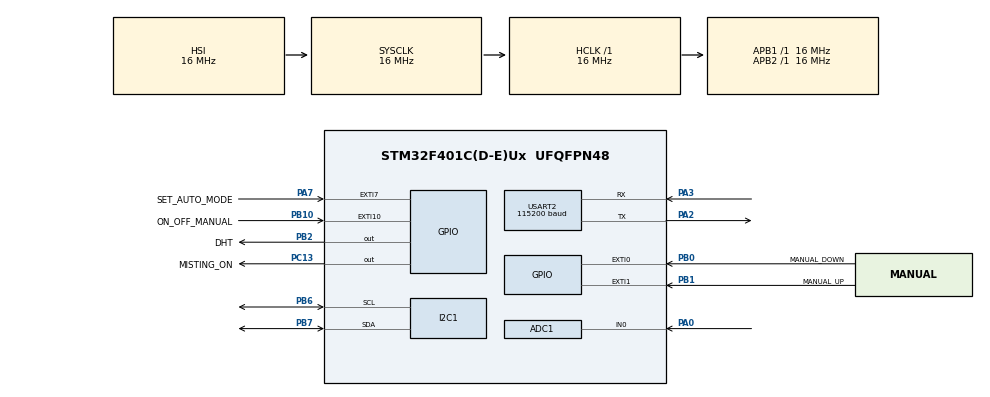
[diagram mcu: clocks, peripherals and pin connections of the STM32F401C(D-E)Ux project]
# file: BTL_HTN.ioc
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ADC1.Channel-0\#ChannelRegularConversion=ADC_CHANNEL_0
ADC1.NbrOfConversionFlag=1
ADC1.Rank-0\#ChannelRegularConversion=1
ADC1.SamplingTime-0\#ChannelRegularConversion=ADC_SAMPLETIME_3CYCLES
ADC1.master=1
Mcu.Family=STM32F4
Mcu.Name=STM32F401C(D-E)Ux
Mcu.Package=UFQFPN48
NVIC.EXTI0_IRQn=true\:4\:0\:true\:false\:true\:true\:true\:true
NVIC.EXTI15_10_IRQn=true\:4\:0\:true\:false\:true\:true\:true\:true
NVIC.EXTI1_IRQn=true\:4\:0\:true\:false\:true\:true\:true\:true
NVIC.EXTI9_5_IRQn=true\:4\:0\:true\:false\:true\:true\:true\:true
NVIC.PriorityGroup=NVIC_PRIORITYGROUP_4
NVIC.TIM3_IRQn=true\:4\:0\:true\:false\:true\:true\:true\:true
NVIC.TIM4_IRQn=true\:4\:0\:true\:false\:true\:true\:true\:true
NVIC.TIM5_IRQn=true\:5\:0\:true\:false\:true\:true\:true\:true
NVIC.USART2_IRQn=true\:3\:0\:true\:false\:true\:true\:true\:true
PA0-WKUP.Signal=ADCx_IN0
PA13.Mode=Serial_Wire
PA13.Signal=SYS_JTMS-SWDIO
PA14.Mode=Serial_Wire
PA14.Signal=SYS_JTCK-SWCLK
PA2.Mode=Asynchronous
PA2.Signal=USART2_TX
PA3.Mode=Asynchronous
PA3.Signal=USART2_RX
PA7.GPIO_Label=SET_AUTO_MODE
PA7.GPIO_ModeDefaultEXTI=GPIO_MODE_IT_FALLING
PA7.GPIO_PuPd=GPIO_PULLDOWN
PA7.Signal=GPXTI7
PB0.GPIO_Label=MANUAL_DOWN
PB0.GPIO_ModeDefaultEXTI=GPIO_MODE_IT_FALLING
PB0.GPIO_PuPd=GPIO_PULLDOWN
PB0.Signal=GPXTI0
PB1.GPIO_Label=MANUAL_UP
PB1.GPIO_ModeDefaultEXTI=GPIO_MODE_IT_FALLING
PB1.GPIO_PuPd=GPIO_PULLDOWN
PB1.Signal=GPXTI1
PB10.GPIO_Label=ON_OFF_MANUAL
PB10.GPIO_ModeDefaultEXTI=GPIO_MODE_IT_FALLING
PB10.GPIO_PuPd=GPIO_PULLDOWN
PB10.Signal=GPXTI10
PB2.GPIO_Label=DHT
PB2.Signal=GPIO_Output
PB6.Mode=I2C
PB6.Signal=I2C1_SCL
PB7.Mode=I2C
PB7.Signal=I2C1_SDA
PC13-ANTI_TAMP.GPIO_Label=MISTING_ON
PC13-ANTI_TAMP.Signal=GPIO_Output
ProjectManager.HeapSize=0x200
ProjectManager.StackSize=0x400
ProjectManager.TargetToolchain=STM32CubeIDE
RCC.AHBFreq_Value=16000000
RCC.APB1Freq_Value=16000000
RCC.APB2Freq_Value=16000000
RCC.CortexFreq_Value=16000000
RCC.HSE_VALUE=25000000
RCC.HSI_VALUE=16000000
RCC.LSE_VALUE=32768
RCC.SYSCLKFreq_VALUE=16000000
RCC.VCOOutputFreq_Value=192000000
SH.ADCx_IN0.0=ADC1_IN0,IN0
TIM2.Prescaler=15
TIM3.Period=399
TIM3.Prescaler=799
TIM4.Period=4999
TIM4.Prescaler=15999
TIM5.Period=49999
TIM5.Prescaler=159
USART2.BaudRate=115200
USART2.VirtualMode=VM_ASYNC
VP_TIM2_VS_ClockSourceINT.Mode=Internal
VP_TIM3_VS_ClockSourceINT.Mode=Internal
VP_TIM4_VS_ClockSourceINT.Mode=Internal
VP_TIM5_VS_ClockSourceINT.Mode=Internal
board=custom

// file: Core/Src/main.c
/* USER CODE BEGIN Header */
/**
  ******************************************************************************
  * @file           : main.c
  * @brief          : Main program body
  ******************************************************************************
  * @attention
  *
  * Copyright (c) 2025 STMicroelectronics.
  * All rights reserved.
  *
  * This software is licensed under terms that can be found in the LICENSE file
  * in the root directory of this software component.
  * If no LICENSE file comes with this software, it is provided AS-IS.
  *
  ******************************************************************************
  */
/* USER CODE END Header */
#include "main.h"

/* USER CODE BEGIN Includes */
#include "app.h"

/* USER CODE END Includes */

ADC_HandleTypeDef hadc1;

I2C_HandleTypeDef hi2c1;

TIM_HandleTypeDef htim2;
TIM_HandleTypeDef htim3;
TIM_HandleTypeDef htim4;
TIM_HandleTypeDef htim5;

UART_HandleTypeDef huart2;

void SystemClock_Config(void);
static void MX_GPIO_Init(void);
static void MX_ADC1_Init(void);
static void MX_TIM3_Init(void);
static void MX_TIM2_Init(void);
static void MX_I2C1_Init(void);
static void MX_USART2_UART_Init(void);
static void MX_TIM4_Init(void);
static void MX_TIM5_Init(void);

int main(void)
{

  /* MCU Configuration--------------------------------------------------------*/

  /* Reset of all peripherals, Initializes the Flash interface and the Systick. */
  HAL_Init();

  /* Configure the system clock */
  SystemClock_Config();

  /* Initialize all configured peripherals */
  MX_GPIO_Init();
  MX_ADC1_Init();
  MX_TIM3_Init();
  MX_TIM2_Init();
  MX_I2C1_Init();
  MX_USART2_UART_Init();
  MX_TIM4_Init();
  MX_TIM5_Init();
  /* USER CODE BEGIN 2 */

	Air_Monitor_Main();
  /* USER CODE END 2 */

  /* Infinite loop */
  while (1)
  {

  }
}

void SystemClock_Config(void)
{
  RCC_OscInitTypeDef RCC_OscInitStruct = {0};
  RCC_ClkInitTypeDef RCC_ClkInitStruct = {0};

  /** Configure the main internal regulator output voltage
  */
  __HAL_RCC_PWR_CLK_ENABLE();
  __HAL_PWR_VOLTAGESCALING_CONFIG(PWR_REGULATOR_VOLTAGE_SCALE2);

  /** Initializes the RCC Oscillators according to the specified parameters
  * in the RCC_OscInitTypeDef structure.
  */
  RCC_OscInitStruct.OscillatorType = RCC_OSCILLATORTYPE_HSI;
  RCC_OscInitStruct.HSIState = RCC_HSI_ON;
  RCC_OscInitStruct.HSICalibrationValue = RCC_HSICALIBRATION_DEFAULT;
  RCC_OscInitStruct.PLL.PLLState = RCC_PLL_NONE;
  if (HAL_RCC_OscConfig(&RCC_OscInitStruct) != HAL_OK)
  {
    Error_Handler();
  }

  /** Initializes the CPU, AHB and APB buses clocks
  */
  RCC_ClkInitStruct.ClockType = RCC_CLOCKTYPE_HCLK|RCC_CLOCKTYPE_SYSCLK
                              |RCC_CLOCKTYPE_PCLK1|RCC_CLOCKTYPE_PCLK2;
  RCC_ClkInitStruct.SYSCLKSource = RCC_SYSCLKSOURCE_HSI;
  RCC_ClkInitStruct.AHBCLKDivider = RCC_SYSCLK_DIV1;
  RCC_ClkInitStruct.APB1CLKDivider = RCC_HCLK_DIV1;
  RCC_ClkInitStruct.APB2CLKDivider = RCC_HCLK_DIV1;

  if (HAL_RCC_ClockConfig(&RCC_ClkInitStruct, FLASH_LATENCY_0) != HAL_OK)
  {
    Error_Handler();
  }
}

static void MX_ADC1_Init(void)
{

  ADC_ChannelConfTypeDef sConfig = {0};

  /** Configure the global features of the ADC (Clock, Resolution, Data Alignment and number of conversion)
  */
  hadc1.Instance = ADC1;
  hadc1.Init.ClockPrescaler = ADC_CLOCK_SYNC_PCLK_DIV2;
  hadc1.Init.Resolution = ADC_RESOLUTION_12B;
  hadc1.Init.ScanConvMode = DISABLE;
  hadc1.Init.ContinuousConvMode = DISABLE;
  hadc1.Init.DiscontinuousConvMode = DISABLE;
  hadc1.Init.ExternalTrigConvEdge = ADC_EXTERNALTRIGCONVEDGE_NONE;
  hadc1.Init.ExternalTrigConv = ADC_SOFTWARE_START;
  hadc1.Init.DataAlign = ADC_DATAALIGN_RIGHT;
  hadc1.Init.NbrOfConversion = 1;
  hadc1.Init.DMAContinuousRequests = DISABLE;
  hadc1.Init.EOCSelection = ADC_EOC_SINGLE_CONV;
  if (HAL_ADC_Init(&hadc1) != HAL_OK)
  {
    Error_Handler();
  }

  /** Configure for the selected ADC regular channel its corresponding rank in the sequencer and its sample time.
  */
  sConfig.Channel = ADC_CHANNEL_0;
  sConfig.Rank = 1;
  sConfig.SamplingTime = ADC_SAMPLETIME_3CYCLES;
  if (HAL_ADC_ConfigChannel(&hadc1, &sConfig) != HAL_OK)
  {
    Error_Handler();
  }

}

static void MX_I2C1_Init(void)
{

  hi2c1.Instance = I2C1;
  hi2c1.Init.ClockSpeed = 100000;
  hi2c1.Init.DutyCycle = I2C_DUTYCYCLE_2;
  hi2c1.Init.OwnAddress1 = 0;
  hi2c1.Init.AddressingMode = I2C_ADDRESSINGMODE_7BIT;
  hi2c1.Init.DualAddressMode = I2C_DUALADDRESS_DISABLE;
  hi2c1.Init.OwnAddress2 = 0;
  hi2c1.Init.GeneralCallMode = I2C_GENERALCALL_DISABLE;
  hi2c1.Init.NoStretchMode = I2C_NOSTRETCH_DISABLE;
  if (HAL_I2C_Init(&hi2c1) != HAL_OK)
  {
    Error_Handler();
  }

}

static void MX_TIM2_Init(void)
{

  TIM_ClockConfigTypeDef sClockSourceConfig = {0};
  TIM_MasterConfigTypeDef sMasterConfig = {0};

  htim2.Instance = TIM2;
  htim2.Init.Prescaler = 15;
  htim2.Init.CounterMode = TIM_COUNTERMODE_UP;
  htim2.Init.Period = 4294967295;
  htim2.Init.ClockDivision = TIM_CLOCKDIVISION_DIV1;
  htim2.Init.AutoReloadPreload = TIM_AUTORELOAD_PRELOAD_DISABLE;
  if (HAL_TIM_Base_Init(&htim2) != HAL_OK)
  {
    Error_Handler();
  }
  sClockSourceConfig.ClockSource = TIM_CLOCKSOURCE_INTERNAL;
  if (HAL_TIM_ConfigClockSource(&htim2, &sClockSourceConfig) != HAL_OK)
  {
    Error_Handler();
  }
  sMasterConfig.MasterOutputTrigger = TIM_TRGO_RESET;
  sMasterConfig.MasterSlaveMode = TIM_MASTERSLAVEMODE_DISABLE;
  if (HAL_TIMEx_MasterConfigSynchronization(&htim2, &sMasterConfig) != HAL_OK)
  {
    Error_Handler();
  }

}

static void MX_TIM3_Init(void)
{

  TIM_ClockConfigTypeDef sClockSourceConfig = {0};
  TIM_MasterConfigTypeDef sMasterConfig = {0};

  htim3.Instance = TIM3;
  htim3.Init.Prescaler = 799;
  htim3.Init.CounterMode = TIM_COUNTERMODE_UP;
  htim3.Init.Period = 399;
  htim3.Init.ClockDivision = TIM_CLOCKDIVISION_DIV1;
  htim3.Init.AutoReloadPreload = TIM_AUTORELOAD_PRELOAD_DISABLE;
  if (HAL_TIM_Base_Init(&htim3) != HAL_OK)
  {
    Error_Handler();
  }
  sClockSourceConfig.ClockSource = TIM_CLOCKSOURCE_INTERNAL;
  if (HAL_TIM_ConfigClockSource(&htim3, &sClockSourceConfig) != HAL_OK)
  {
    Error_Handler();
  }
  sMasterConfig.MasterOutputTrigger = TIM_TRGO_RESET;
  sMasterConfig.MasterSlaveMode = TIM_MASTERSLAVEMODE_DISABLE;
  if (HAL_TIMEx_MasterConfigSynchronization(&htim3, &sMasterConfig) != HAL_OK)
  {
    Error_Handler();
  }

}

static void MX_TIM4_Init(void)
{

  TIM_ClockConfigTypeDef sClockSourceConfig = {0};
  TIM_MasterConfigTypeDef sMasterConfig = {0};

  htim4.Instance = TIM4;
  htim4.Init.Prescaler = 15999;
  htim4.Init.CounterMode = TIM_COUNTERMODE_UP;
  htim4.Init.Period = 4999;
  htim4.Init.ClockDivision = TIM_CLOCKDIVISION_DIV1;
  htim4.Init.AutoReloadPreload = TIM_AUTORELOAD_PRELOAD_DISABLE;
  if (HAL_TIM_Base_Init(&htim4) != HAL_OK)
  {
    Error_Handler();
  }
  sClockSourceConfig.ClockSource = TIM_CLOCKSOURCE_INTERNAL;
  if (HAL_TIM_ConfigClockSource(&htim4, &sClockSourceConfig) != HAL_OK)
  {
    Error_Handler();
  }
  sMasterConfig.MasterOutputTrigger = TIM_TRGO_RESET;
  sMasterConfig.MasterSlaveMode = TIM_MASTERSLAVEMODE_DISABLE;
  if (HAL_TIMEx_MasterConfigSynchronization(&htim4, &sMasterConfig) != HAL_OK)
  {
    Error_Handler();
  }

}

static void MX_TIM5_Init(void)
{

  TIM_ClockConfigTypeDef sClockSourceConfig = {0};
  TIM_MasterConfigTypeDef sMasterConfig = {0};

  htim5.Instance = TIM5;
  htim5.Init.Prescaler = 159;
  htim5.Init.CounterMode = TIM_COUNTERMODE_UP;
  htim5.Init.Period = 49999;
  htim5.Init.ClockDivision = TIM_CLOCKDIVISION_DIV1;
  htim5.Init.AutoReloadPreload = TIM_AUTORELOAD_PRELOAD_DISABLE;
  if (HAL_TIM_Base_Init(&htim5) != HAL_OK)
  {
    Error_Handler();
  }
  sClockSourceConfig.ClockSource = TIM_CLOCKSOURCE_INTERNAL;
  if (HAL_TIM_ConfigClockSource(&htim5, &sClockSourceConfig) != HAL_OK)
  {
    Error_Handler();
  }
  sMasterConfig.MasterOutputTrigger = TIM_TRGO_RESET;
  sMasterConfig.MasterSlaveMode = TIM_MASTERSLAVEMODE_DISABLE;
  if (HAL_TIMEx_MasterConfigSynchronization(&htim5, &sMasterConfig) != HAL_OK)
  {
    Error_Handler();
  }

}

static void MX_USART2_UART_Init(void)
{

  huart2.Instance = USART2;
  huart2.Init.BaudRate = 115200;
  huart2.Init.WordLength = UART_WORDLENGTH_8B;
  huart2.Init.StopBits = UART_STOPBITS_1;
  huart2.Init.Parity = UART_PARITY_NONE;
  huart2.Init.Mode = UART_MODE_TX_RX;
  huart2.Init.HwFlowCtl = UART_HWCONTROL_NONE;
  huart2.Init.OverSampling = UART_OVERSAMPLING_16;
  if (HAL_UART_Init(&huart2) != HAL_OK)
  {
    Error_Handler();
  }

}

static void MX_GPIO_Init(void)
{
  GPIO_InitTypeDef GPIO_InitStruct = {0};

  /* GPIO Ports Clock Enable */
  __HAL_RCC_GPIOC_CLK_ENABLE();
  __HAL_RCC_GPIOA_CLK_ENABLE();
  __HAL_RCC_GPIOB_CLK_ENABLE();

  /*Configure GPIO pin Output Level */
  HAL_GPIO_WritePin(MISTING_ON_GPIO_Port, MISTING_ON_Pin, GPIO_PIN_RESET);

  /*Configure GPIO pin Output Level */
  HAL_GPIO_WritePin(DHT_GPIO_Port, DHT_Pin, GPIO_PIN_RESET);

  /*Configure GPIO pin : MISTING_ON_Pin */
  GPIO_InitStruct.Pin = MISTING_ON_Pin;
  GPIO_InitStruct.Mode = GPIO_MODE_OUTPUT_PP;
  GPIO_InitStruct.Pull = GPIO_NOPULL;
  GPIO_InitStruct.Speed = GPIO_SPEED_FREQ_LOW;
  HAL_GPIO_Init(MISTING_ON_GPIO_Port, &GPIO_InitStruct);

  /*Configure GPIO pin : SET_AUTO_MODE_Pin */
  GPIO_InitStruct.Pin = SET_AUTO_MODE_Pin;
  GPIO_InitStruct.Mode = GPIO_MODE_IT_FALLING;
  GPIO_InitStruct.Pull = GPIO_PULLDOWN;
  HAL_GPIO_Init(SET_AUTO_MODE_GPIO_Port, &GPIO_InitStruct);

  /*Configure GPIO pins : MANUAL_DOWN_Pin MANUAL_UP_Pin ON_OFF_MANUAL_Pin */
  GPIO_InitStruct.Pin = MANUAL_DOWN_Pin|MANUAL_UP_Pin|ON_OFF_MANUAL_Pin;
  GPIO_InitStruct.Mode = GPIO_MODE_IT_FALLING;
  GPIO_InitStruct.Pull = GPIO_PULLDOWN;
  HAL_GPIO_Init(GPIOB, &GPIO_InitStruct);

  /*Configure GPIO pin : DHT_Pin */
  GPIO_InitStruct.Pin = DHT_Pin;
  GPIO_InitStruct.Mode = GPIO_MODE_OUTPUT_PP;
  GPIO_InitStruct.Pull = GPIO_NOPULL;
  GPIO_InitStruct.Speed = GPIO_SPEED_FREQ_LOW;
  HAL_GPIO_Init(DHT_GPIO_Port, &GPIO_InitStruct);

  /* EXTI interrupt init*/
  HAL_NVIC_SetPriority(EXTI0_IRQn, 4, 0);
  HAL_NVIC_EnableIRQ(EXTI0_IRQn);

  HAL_NVIC_SetPriority(EXTI1_IRQn, 4, 0);
  HAL_NVIC_EnableIRQ(EXTI1_IRQn);

  HAL_NVIC_SetPriority(EXTI9_5_IRQn, 4, 0);
  HAL_NVIC_EnableIRQ(EXTI9_5_IRQn);

  HAL_NVIC_SetPriority(EXTI15_10_IRQn, 4, 0);
  HAL_NVIC_EnableIRQ(EXTI15_10_IRQn);

}

void Error_Handler(void)
{
  __disable_irq();
  while (1)
  {
  }
}
